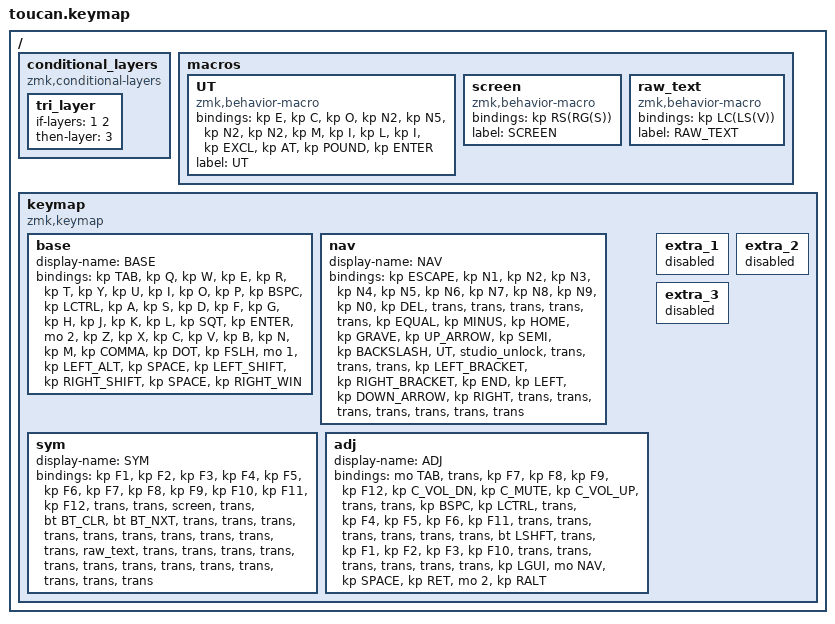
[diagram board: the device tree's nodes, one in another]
#include <behaviors.dtsi>
#include <dt-bindings/zmk/bt.h>
#include <dt-bindings/zmk/keys.h>

#define BASE 0
#define NAV  1
#define SYM  2
#define ADJ  3

/ {
    conditional_layers {
        compatible = "zmk,conditional-layers";

        tri_layer {
            if-layers = <1 2>;
            then-layer = <3>;
        };
    };

    macros {
        UT: UT {
            compatible = "zmk,behavior-macro";
            #binding-cells = <0>;
            bindings = <&kp E &kp C &kp O &kp N2 &kp N5 &kp N2 &kp N2 &kp M &kp I &kp L &kp I &kp EXCL &kp AT &kp POUND &kp ENTER>;
            label = "UT";
        };

        screen: screen {
            compatible = "zmk,behavior-macro";
            #binding-cells = <0>;
            bindings = <&kp RS(RG(S))>;
            label = "SCREEN";
        };

        raw_text: raw_text {
            compatible = "zmk,behavior-macro";
            #binding-cells = <0>;
            bindings = <&kp LC(LS(V))>;
            label = "RAW_TEXT";
        };
    };

    keymap {
        compatible = "zmk,keymap";

        base {
            display-name = "BASE";
            bindings = <
&kp TAB  &kp Q  &kp W  &kp E  &kp R  &kp T  &kp Y  &kp U  &kp I  &kp O  &kp P  &kp BSPC  &kp LCTRL  &kp A  &kp S  &kp D  &kp F  &kp G  &kp H  &kp J  &kp K  &kp L  &kp SQT  &kp ENTER  &mo 2  &kp Z  &kp X  &kp C  &kp V  &kp B  &kp N  &kp M  &kp COMMA  &kp DOT  &kp FSLH  &mo 1  &kp LEFT_ALT  &kp SPACE  &kp LEFT_SHIFT  &kp RIGHT_SHIFT  &kp SPACE  &kp RIGHT_WIN
            >;
        };

        nav {
            display-name = "NAV";
            bindings = <
&kp ESCAPE  &kp N1  &kp N2  &kp N3  &kp N4  &kp N5  &kp N6  &kp N7  &kp N8  &kp N9  &kp N0  &kp DEL  &trans  &trans  &trans  &trans  &trans  &kp EQUAL  &kp MINUS  &kp HOME  &kp GRAVE  &kp UP_ARROW  &kp SEMI  &kp BACKSLASH  &UT  &studio_unlock  &trans  &trans  &trans  &kp LEFT_BRACKET  &kp RIGHT_BRACKET  &kp END  &kp LEFT  &kp DOWN_ARROW  &kp RIGHT  &trans  &trans  &trans  &trans  &trans  &trans  &trans
            >;
        };

        sym {
            display-name = "SYM";
            bindings = <
&kp F1  &kp F2  &kp F3  &kp F4  &kp F5  &kp F6  &kp F7  &kp F8  &kp F9  &kp F10  &kp F11  &kp F12  &trans  &trans  &screen  &trans  &bt BT_CLR  &bt BT_NXT  &trans  &trans  &trans  &trans  &trans  &trans  &trans  &trans  &trans  &trans  &raw_text  &trans  &trans  &trans  &trans  &trans  &trans  &trans  &trans  &trans  &trans  &trans  &trans  &trans
            >;
        };

        adj {
            display-name = "ADJ";
            bindings = <
&mo TAB  &trans  &kp F7  &kp F8  &kp F9  &kp F12  &kp C_VOL_DN  &kp C_MUTE  &kp C_VOL_UP  &trans  &trans  &kp BSPC  &kp LCTRL  &trans  &kp F4  &kp F5  &kp F6  &kp F11  &trans  &trans  &trans  &trans  &trans  &trans  &bt LSHFT  &trans  &kp F1  &kp F2  &kp F3  &kp F10  &trans  &trans  &trans  &trans  &trans  &trans  &kp LGUI  &mo NAV  &kp SPACE  &kp RET  &mo 2  &kp RALT
            >;
        };

        extra_1 { status = "reserved"; };

        extra_2 { status = "reserved"; };

        extra_3 { status = "reserved"; };
    };
};
